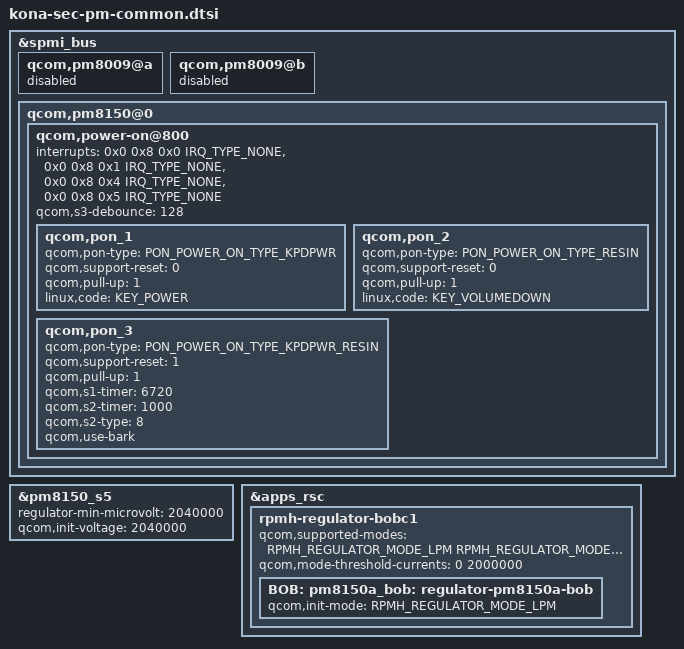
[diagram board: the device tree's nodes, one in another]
/* Copyright (c) 2014, The Linux Foundation. All rights reserved.
 *
 * This program is free software; you can redistribute it and/or modify
 * it under the terms of the GNU General Public License version 2 and
 * only version 2 as published by the Free Software Foundation.
 *
 * This program is distributed in the hope that it will be useful,
 * but WITHOUT ANY WARRANTY; without even the implied warranty of
 * MERCHANTABILITY or FITNESS FOR A PARTICULAR PURPOSE.  See the
 * GNU General Public License for more details.
 */

#include <dt-bindings/regulator/qcom,rpmh-regulator-levels.h>

&spmi_bus {
	qcom,pm8009@a {
		status = "disabled";
	};
	qcom,pm8009@b {
		status = "disabled";
	};
};

&pm8150_s5 {
	regulator-min-microvolt = <2040000>;
	qcom,init-voltage = <2040000>;
};

&spmi_bus {
	qcom,pm8150@0 {
		qcom,power-on@800 {
			interrupts = <0x0 0x8 0x0 IRQ_TYPE_NONE>,
				     <0x0 0x8 0x1 IRQ_TYPE_NONE>,
					 <0x0 0x8 0x4 IRQ_TYPE_NONE>,
				     <0x0 0x8 0x5 IRQ_TYPE_NONE>;
			interrupt-names = "kpdpwr", "resin",
                    "resin-bark", "kpdpwr-resin-bark";

			qcom,s3-debounce = <128>;
			qcom,pon_1 {
				qcom,pon-type = <PON_POWER_ON_TYPE_KPDPWR>;
				qcom,support-reset = <0>;
				qcom,pull-up = <1>;
				linux,code = <KEY_POWER>;
			};

			qcom,pon_2 {
				qcom,pon-type = <PON_POWER_ON_TYPE_RESIN>;
				qcom,support-reset = <0>;
				qcom,pull-up = <1>;
				linux,code = <KEY_VOLUMEDOWN>;
			};

			qcom,pon_3 {
				qcom,pon-type = <PON_POWER_ON_TYPE_KPDPWR_RESIN>;
				qcom,support-reset = <1>;
				qcom,pull-up = <1>;
				qcom,s1-timer = <6720>;
				qcom,s2-timer = <1000>;
				qcom,s2-type = <8>;
				qcom,use-bark;
			};
		};
	};
};

&apps_rsc {
	/* H/W request */
	rpmh-regulator-bobc1 {
		qcom,supported-modes =
			<RPMH_REGULATOR_MODE_LPM
			 RPMH_REGULATOR_MODE_HPM>;
		qcom,mode-threshold-currents = <0 2000000>;

		BOB: pm8150a_bob: regulator-pm8150a-bob {
			qcom,init-mode = <RPMH_REGULATOR_MODE_LPM>;
		};
	};
};
